# ESP32-H4 register map
Vendor: ESPRESSIF SYSTEMS (SHANGHAI) CO., LTD.; Series: ESP32 H-Series; File version: 1
CPU: RV32IMAC r0p0, little endian, no MPU, no FPU, 0 interrupt priority bits
Address unit: 32 bits
Registers are 32-bit, read-write, reset 0x0 unless marked. A register's access mark holds for its fields unless they carry their own. Offsets are from the block's base; [hi:lo] are bit positions; {n}, {i} and the like mark numbered series.

## LP_WDT — Low-power Watchdog Timer
Base 0x600B5400
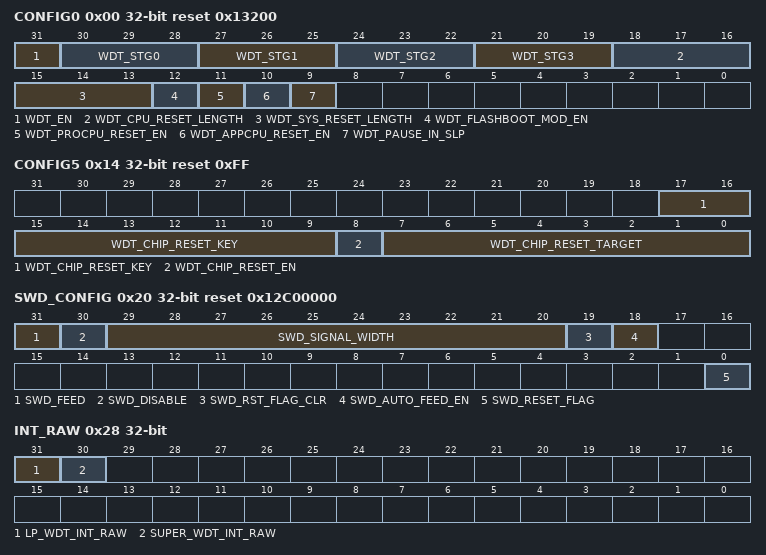
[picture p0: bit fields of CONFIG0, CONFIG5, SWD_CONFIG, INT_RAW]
0x00 CONFIG0 reset 0x13200 — Configure the RWDT operation.
  [31] WDT_EN — Configure whether or not to enable RWDT.\\0:Disable \\1:Enable
  [30-3n:28-3n] WDT_STG{n} (n=0..3) — Configure the timeout action of stage{n}.\\0: No operation \\1:Generate interrupt \\2 :Generate HP CPU reset \\3:Generate HP core reset \\4 :Generate system reset.
  [18:16] WDT_CPU_RESET_LENGTH — Configure the HP CPU reset time.\\Measurement unit: LP\_DYN\_FAST\_CLK
  [15:13] WDT_SYS_RESET_LENGTH — Configure the HP core reset time.\\Measurement unit: LP\_DYN\_FAST\_CLK
  [12] WDT_FLASHBOOT_MOD_EN — Configure whether or not enable RWDT when chip is in SPI boot mode.\\0:Disable \\1:Enable
  [11] WDT_PROCPU_RESET_EN — need_des
  [10] WDT_APPCPU_RESET_EN — Configure whether or not to enable RWDT to reset CPU.\\0:Disable \\1:Enable
  [9] WDT_PAUSE_IN_SLP — Configure whether or not pause RWDT when chip is in sleep mode.\\0:Enable \\1:Disable
0x04 CONFIG1 reset 0x30D40 — Configure the RWDT timeout of stage0
  [31:0] WDT_STG0_HOLD — Configure the timeout time for stage0. \\Measurement unit: LP\_DYN\_SLOW\_CLK
0x08 CONFIG2 reset 0x13880 — Configure the RWDT timeout of stage1
  [31:0] WDT_STG1_HOLD — Configure the timeout time for stage1. \\Measurement unit: LP\_DYN\_SLOW\_CLK
0x0C CONFIG3 reset 0xFFF — Configure the RWDT timeout of stage2
  [31:0] WDT_STG2_HOLD — Configure the timeout time for stage2. \\Measurement unit: LP\_DYN\_SLOW\_CLK
0x10 CONFIG4 reset 0xFFF — Configure the RWDT timeout of stage3
  [31:0] WDT_STG3_HOLD — Configure the timeout time for stage3. \\Measurement unit: LP\_DYN\_SLOW\_CLK
0x14 CONFIG5 reset 0xFF — Configure the RWDT timeout of stage3
  [17:9] WDT_CHIP_RESET_KEY — need_des
  [8] WDT_CHIP_RESET_EN — need_des
  [7:0] WDT_CHIP_RESET_TARGET — need_des
0x18 FEED wo — Configure the feed function of RWDT
  [31] RTC_WDT_FEED — Configure this bit to feed the RWDT.\\ 0: Invalid\\ 1: Feed RWDT
0x1C WPROTECT — Configure the lock function of SWD
  [31:0] WDT_WKEY — Configure this field to lock or unlock RWDT`s configuration registers.\\0x50D83AA1: unlock the RWDT configuration registers.\\ Others value: Lock the RWDT configuration register which can`t be modified by software.
0x20 SWD_CONFIG access per field reset 0x12C00000 — Configure the SWD operation
  [31] SWD_FEED wo — Configure this bit to feed the SWD.\\ 0: Invalid\\ 1: Feed SWD
  [30] SWD_DISABLE rw — Configure this bit to disable the SWD.\\ 0: Enable the SWD\\ 1: Disable the SWD
  [29:20] SWD_SIGNAL_WIDTH rw — Configure the SWD signal length that output to analog circuit. \\ Measurement unit: LP\_DYN\_FAST\_CLK
  [19] SWD_RST_FLAG_CLR wo — Configure this bit to clear SWD reset flag.\\ 0:Invalid \\ 1: Clear the reset flag
  [18] SWD_AUTO_FEED_EN rw — Configure this bit to enable to feed SWD automatically by hardware. \\0: Disable \\1: Enable
  [0] SWD_RESET_FLAG ro — Represents the SWD whether has generated the reset signal.\\0 :No \\1: Yes
0x24 SWD_WPROTECT — Configure the lock function of SWD
  [31:0] SWD_WKEY — Configure this field to lock or unlock SWD`s configuration registers.\\0x50D83AA1: unlock the RWDT configuration registers.\\ Others value: Lock the RWDT configuration register which can`t be modified by software.
0x28 INT_RAW — Configure whether to generate timeout interrupt
  [31] LP_WDT_INT_RAW — Represents the RWDT whether or not generates timeout interrupt.\\ 0:No \\1: Yes
  [30] SUPER_WDT_INT_RAW — Represents the SWD whether or not generates timeout interrupt.\\ 0:No \\1: Yes
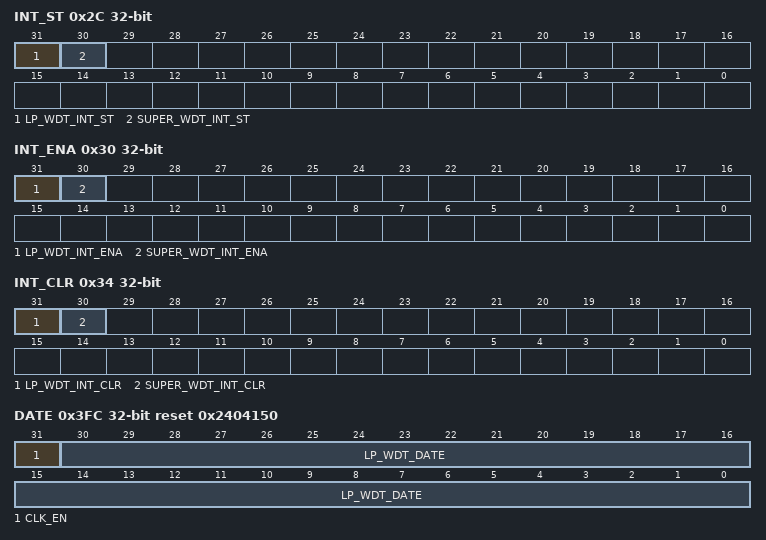
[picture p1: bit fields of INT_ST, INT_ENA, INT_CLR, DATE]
0x2C INT_ST ro — The interrupt status register of WDT
  [31] LP_WDT_INT_ST — Represents the RWDT whether or not has generated and sent timeout interrupt to CPU.\\ 0:No \\1: Yes
  [30] SUPER_WDT_INT_ST — Represents the SWD whether or not has generated and sent timeout interrupt to CPU.\\ 0:No \\1: Yes
0x30 INT_ENA — The interrupt enable register of WDT
  [31] LP_WDT_INT_ENA — Configure whether or not to enable the RWDT to send timeout interrupt.\\0:Disable \\1:Enable
  [30] SUPER_WDT_INT_ENA — Configure whether or not to enable the SWD to send timeout interrupt.\\0:Disable \\1:Enable
0x34 INT_CLR wo — The interrupt clear register of WDT
  [31] LP_WDT_INT_CLR — Configure whether to clear the timeout interrupt signal sent by RWDT to CPU.\\0: No\\1: Yes
  [30] SUPER_WDT_INT_CLR — Configure whether to clear the timeout interrupt signal sent by SWD to CPU.\\0: No\\1: Yes
0x3FC DATE reset 0x2404150 — need_des
  [31] CLK_EN — Reserved
  [30:0] LP_WDT_DATE — Version control register
